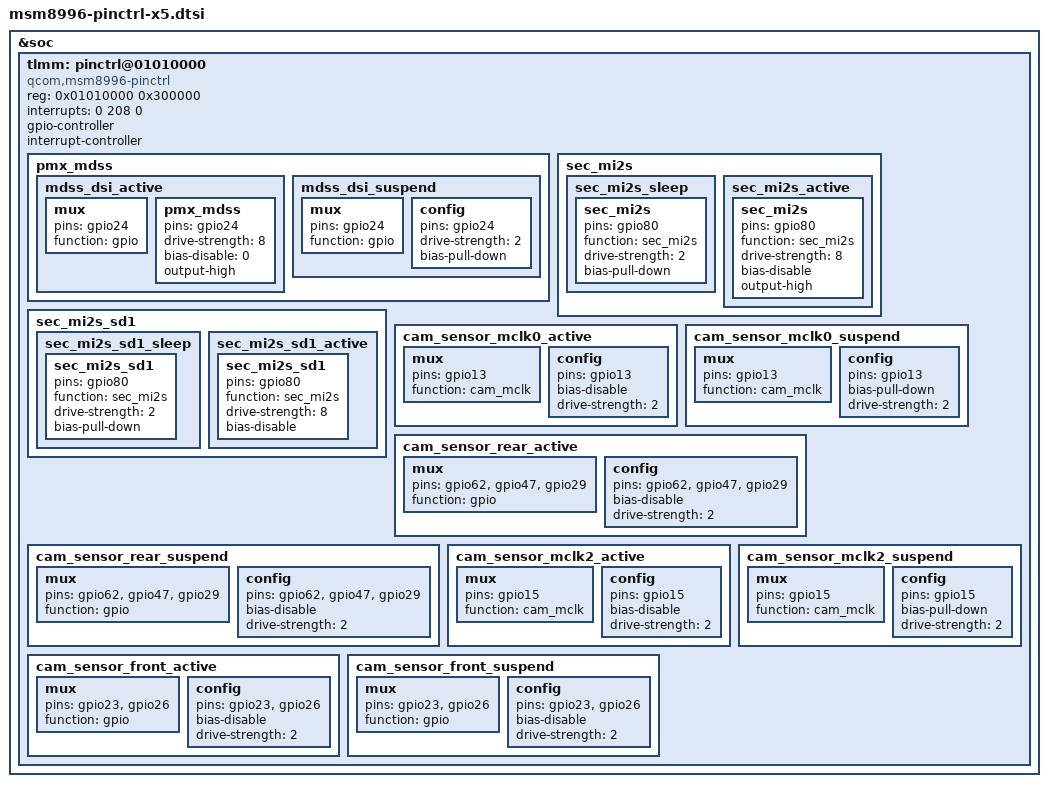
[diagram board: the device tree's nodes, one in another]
/* Copyright (c) 2014-2015, The Linux Foundation. All rights reserved.
 *
 * This program is free software; you can redistribute it and/or modify
 * it under the terms of the GNU General Public License version 2 and
 * only version 2 as published by the Free Software Foundation.
 *
 * This program is distributed in the hope that it will be useful,
 * but WITHOUT ANY WARRANTY; without even the implied warranty of
 * MERCHANTABILITY or FITNESS FOR A PARTICULAR PURPOSE.  See the
 * GNU General Public License for more details.
 */

&soc {
	tlmm: pinctrl@01010000 {
		compatible = "qcom,msm8996-pinctrl";
		reg = <0x01010000 0x300000>;
		interrupts = <0 208 0>;
		gpio-controller;
		#gpio-cells = <2>;
		interrupt-controller;
		#interrupt-cells = <2>;

/*********** lcd gpio config start ***********/
		pmx_mdss: pmx_mdss {
			mdss_dsi_active: mdss_dsi_active {
				mux {
					pins = "gpio24";
					function = "gpio";
				};

				pmx_mdss {
					pins = "gpio24";
					drive-strength = <8>; /* 8 mA */
					bias-disable = <0>; /* no pull */
					output-high;
				};
			};
			mdss_dsi_suspend: mdss_dsi_suspend {
				mux {
					pins = "gpio24";
					function = "gpio";
				};

				config {
					pins = "gpio24";
					drive-strength = <2>; /* 2 mA */
					bias-pull-down;	/* pull	down */
				};
			};
		};
/*********** lcd gpio config end ***********/

/***********redefine sec_mi2s to release gpio81 start********/
		sec_mi2s {
			sec_mi2s_sleep: sec_mi2s_sleep {
				sec_mi2s {
					pins = "gpio80";
					function = "sec_mi2s";
					drive-strength = <2>;	/* 2 mA */
					bias-pull-down;		/* PULL DOWN */
				};
			};
			sec_mi2s_active: sec_mi2s_active {
				sec_mi2s {
					pins = "gpio80";
					function = "sec_mi2s";
					drive-strength = <8>;	/* 8 mA */
					bias-disable;		/* NO PULL */
					output-high;
				};
			};
		};

		sec_mi2s_sd1 {
			sec_mi2s_sd1_sleep: sec_mi2s_sd1_sleep {
				sec_mi2s_sd1 {
					pins = "gpio80";
					function = "sec_mi2s";
					drive-strength = <2>;   /* 2 mA */
					bias-pull-down;         /* PULL DOWN */
				};
			};
			sec_mi2s_sd1_active: sec_mi2s_sd1_active {
				sec_mi2s_sd1 {
					pins = "gpio80";
					function = "sec_mi2s";
					drive-strength = <8>;   /* 8 mA */
					bias-disable;           /* NO PULL */
				};
			};
		};

/***********redefine sec_mi2s to release gpio81 end********/

/*********** Rear/Front Camera config start ***********/
		cam_sensor_mclk0_active: cam_sensor_mclk0_active {
			/* MCLK0 */
			mux {
				/* CLK, DATA */
				pins = "gpio13";
				function = "cam_mclk";
			};

			config {
				pins = "gpio13";
				bias-disable; /* No PULL */
				drive-strength = <2>; /* 2 MA */
			};
		};

		cam_sensor_mclk0_suspend: cam_sensor_mclk0_suspend {
			/* MCLK0 */
			mux {
				/* CLK, DATA */
				pins = "gpio13";
				function = "cam_mclk";
			};

			config {
				pins = "gpio13";
				bias-pull-down; /* PULL DOWN */
				drive-strength = <2>; /* 2 MA */
			};
		};

		cam_sensor_rear_active: cam_sensor_rear_active {
			/* FLASH, AF, STANDBY */
			mux {
				pins = "gpio62", "gpio47", "gpio29";
				function = "gpio";
			};

			config {
				pins = "gpio62", "gpio47", "gpio29";
				bias-disable; /* No PULL */
				drive-strength = <2>; /* 2 MA */
			};
		};

		cam_sensor_rear_suspend: cam_sensor_rear_suspend{
			/* FLASH, AF, STANDBY */
			mux {
				pins = "gpio62", "gpio47", "gpio29";
				function = "gpio";
			};

			config {
				pins = "gpio62", "gpio47", "gpio29";
				bias-disable; /* No PULL */
				drive-strength = <2>; /* 2 MA */
			};
		};

		cam_sensor_mclk2_active: cam_sensor_mclk2_active {
			/* MCLK1 */
			mux {
				/* CLK, DATA */
				pins = "gpio15";
				function = "cam_mclk";
			};

			config {
				pins = "gpio15";
				bias-disable; /* No PULL */
				drive-strength = <2>; /* 2 MA */
			};
		};

		cam_sensor_mclk2_suspend: cam_sensor_mclk2_suspend{
			/* MCLK1 */
			mux {
				/* CLK, DATA */
				pins = "gpio15";
				function = "cam_mclk";
			};

			config {
				pins = "gpio15";
				bias-pull-down; /* PULL DOWN */
				drive-strength = <2>; /* 2 MA */
			};
		};

		cam_sensor_front_active: cam_sensor_front_active{
			/* RESET, STANDBY */
			mux {
				pins = "gpio23","gpio26";
				function = "gpio";
			};

			config {
				pins = "gpio23","gpio26";
				bias-disable; /* No PULL */
				drive-strength = <2>; /* 2 MA */
			};
		};

		cam_sensor_front_suspend: cam_sensor_front_suspend{
			/* RESET, STANDBY */
			mux {
				pins = "gpio23","gpio26";
				function = "gpio";
			};

			config {
				pins = "gpio23","gpio26";
				bias-disable; /* No PULL */
				drive-strength = <2>; /* 2 MA */
			};
		};
/*********** Rear/Front Camera config end ***********/
	};
};
